# f28e12x_dma_ch_regs register map
Vendor: Texas Instruments
Peripheral module from a debugger description file (folder C2000).
Address unit: 16 bits
Registers are 16-bit, read-write, no defined reset value unless marked. A register's access mark holds for its fields unless they carry their own. Offsets are as the file gives them; lines under a group give offsets from that group; [hi:lo] are bit positions; {n}, {i} and the like mark numbered series; 'fields as' and 'values as' point back to an identical list; <NAME> marks a mode.

## DMA_CH_REGS — DMA CH Registers
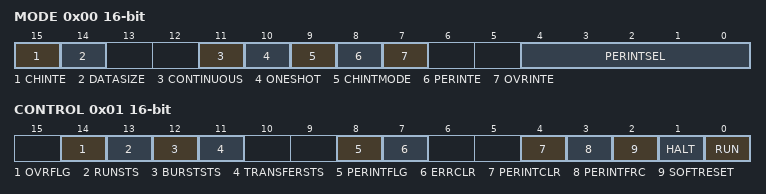
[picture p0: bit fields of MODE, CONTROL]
0x00 MODE
  [15] CHINTE — Channel Interrupt Enable Bit
  [14] DATASIZE — Data Size Mode Bit
  [11] CONTINUOUS — Continuous Mode Bit
  [10] ONESHOT — One Shot Mode Bit
  [9] CHINTMODE — Channel Interrupt Mode
  [8] PERINTE — Peripheral Interrupt Enable
  [7] OVRINTE — Overflow Interrupt Enable
  [4:0] PERINTSEL — Peripheral Interrupt and Sync Select
0x01 CONTROL access per field
  [14] OVRFLG ro — Overflow Flag Bit
  [13] RUNSTS ro — Run Status Bit
  [12] BURSTSTS ro — Burst Status Bit
  [11] TRANSFERSTS ro — Transfer Status Bit
  [8] PERINTFLG ro — Interrupt Flag Bit
  [7] ERRCLR rw — Error Clear Bit
  [4] PERINTCLR rw — Interrupt Clear Bit
  [3] PERINTFRC rw — Interrupt Force Bit
  [2] SOFTRESET rw — Soft Reset Bit
  [1] HALT rw — Halt Bit
  [0] RUN rw — Run Bit
0x02 BURST_SIZE
  [4:0] BURSTSIZE — Burst Transfer Size
0x03 BURST_COUNT ro
  [4:0] BURSTCOUNT — Burst Transfer Size
0x04 SRC_BURST_STEP — Source Burst Step Register
  [15:0] SRCBURSTSTEP — Source post-increment/decrement step size of a burst
0x05 DST_BURST_STEP — Destination Burst Step Register
  [15:0] DSTBURSTSTEP — Destination post-increment/decrement step size of a burst
0x06 TRANSFER_SIZE
  [8:0] TRANSFERSIZE — These bits specify the number of bursts to transfer:
0x07 TRANSFER_COUNT ro
  [8:0] TRANSFERCOUNT — These bits specify the current transfer counter value:
0x08 SRC_TRANSFER_STEP — Source Transfer Step Register
  [15:0] SRCTRANSFERSTEP — Source post-increment/decrement step size of a transfer
0x09 DST_TRANSFER_STEP — Destination Transfer Step Register
  [15:0] DSTTRANSFERSTEP — Destination post-increment/decrement step size of a transfer
0x0A SRC_WRAP_SIZE — Source Wrap Size Register
  [8:0] WRAPSIZE — Number of bursts to transfer before wrapping
0x0B SRC_WRAP_COUNT ro — Source Wrap Count Register
  [8:0] WRAPSIZE — These bits indicate the current wrap counter value:
0x0C SRC_WRAP_STEP — Source Wrap Step Register
  [15:0] WRAPSTEP — Source post-increment/decrement step size for a wrap
0x0D DST_WRAP_SIZE — Destination Wrap Size Register
  [8:0] WRAPSIZE — Number of bursts to transfer before wrapping
0x0E DST_WRAP_COUNT ro — Destination Wrap Count Register
  [8:0] WRAPSIZE — These bits indicate the current wrap counter value:
0x0F DST_WRAP_STEP — Destination Wrap Step Register
  [15:0] WRAPSTEP — Destination post-increment/decrement step size for a wrap
0x10 SRC_BEG_ADDR_SHADOW 32-bit — Source Begin Address Shadow Register
  [31:0] BEGADDR — 32-bit address value
0x12 SRC_ADDR_SHADOW 32-bit — Source Address Shadow Register
  [31:0] ADDR — 32-bit address value
0x14 SRC_BEG_ADDR_ACTIVE 32-bit ro — Source Begin Address Active Register
  [31:0] BEGADDR — 32-bit address value
0x16 SRC_ADDR_ACTIVE 32-bit ro — Source Address Active Register
  [31:0] ADDR — 32-bit address value
0x18 DST_BEG_ADDR_SHADOW 32-bit — Destination Begin Address Shadow Register
  [31:0] BEGADDR — 32-bit address value
0x1A DST_ADDR_SHADOW 32-bit — Destination Address Shadow Register
  [31:0] ADDR — 32-bit address value
0x1C DST_BEG_ADDR_ACTIVE 32-bit ro — Destination Begin Address Active Register
  [31:0] BEGADDR — 32-bit address value
0x1E DST_ADDR_ACTIVE 32-bit ro — Destination Address Active Register
  [31:0] ADDR — 32-bit address value
